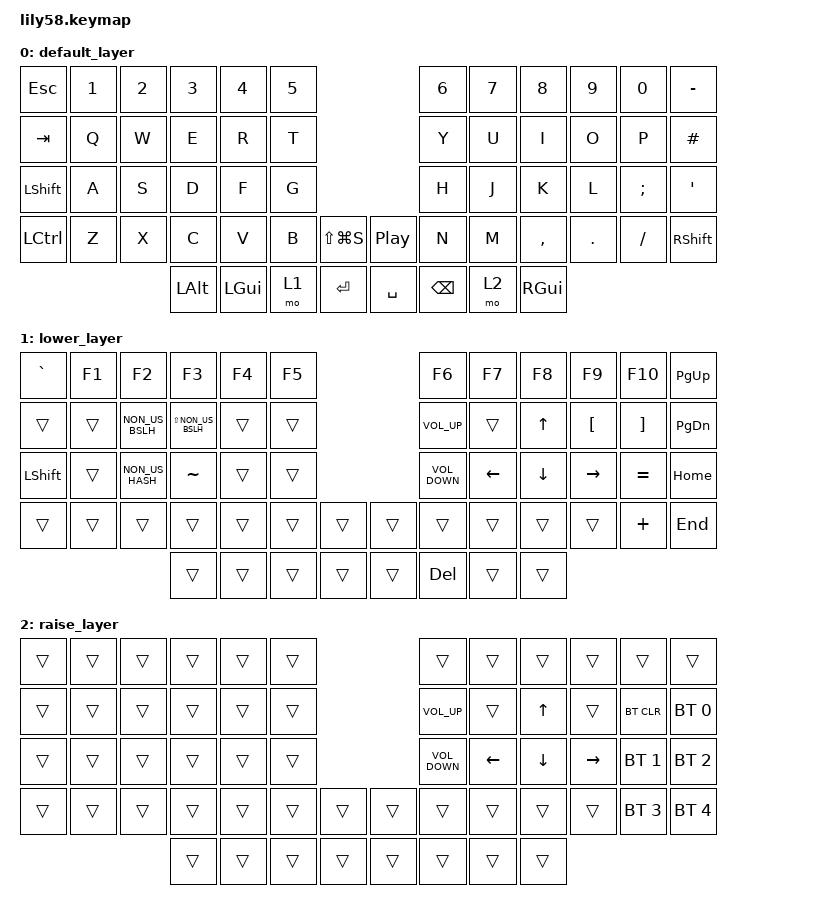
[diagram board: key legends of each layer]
/*
 * Copyright (c) 2020 The ZMK Contributors
 *
 * SPDX-License-Identifier: MIT
 */

#include <behaviors.dtsi>
#include <dt-bindings/zmk/bt.h>
#include <dt-bindings/zmk/keys.h>

/ {
    keymap {
        compatible = "zmk,keymap";

        default_layer {
            bindings = <
&kp ESC   &kp N1  &kp N2  &kp N3    &kp N4    &kp N5                            &kp N6    &kp N7  &kp N8     &kp N9   &kp N0    &kp MINUS
&kp TAB   &kp Q   &kp W   &kp E     &kp R     &kp T                             &kp Y     &kp U   &kp I      &kp O    &kp P     &kp POUND
&kp LSHIFT&kp A   &kp S   &kp D     &kp F     &kp G                             &kp H     &kp J   &kp K      &kp L    &kp SEMI  &kp SQT
&kp LCTRL &kp Z   &kp X   &kp C     &kp V     &kp B   &kp LS(LG(S))  &kp C_PP   &kp N     &kp M   &kp COMMA  &kp DOT  &kp FSLH  &kp RSHFT
                          &kp LALT  &kp LGUI  &mo 1   &kp RETURN     &kp SPACE  &kp BSPC  &mo 2   &kp RGUI
            >;
        };

        lower_layer {
            bindings = <
&kp GRAVE     &kp F1  &kp F2           &kp F3               &kp F4  &kp F5                  &kp F6             &kp F7    &kp F8    &kp F9     &kp F10    &kp PG_UP
&trans        &trans  &kp NON_US_BSLH  &kp LS(NON_US_BSLH)  &trans  &trans                  &kp C_VOLUME_UP    &trans    &kp UP    &kp LBKT   &kp RBKT   &kp PG_DN
&kp LEFT_SHIFT&trans  &kp NON_US_HASH  &kp TILDE            &trans  &trans                  &kp C_VOLUME_DOWN  &kp LEFT  &kp DOWN  &kp RIGHT  &kp EQUAL  &kp HOME
&trans        &trans  &trans           &trans               &trans  &trans  &trans  &trans  &trans             &trans    &trans    &trans     &kp PLUS   &kp END
                                       &trans               &trans  &trans  &trans  &trans  &kp DEL            &trans    &trans
            >;
        };

        raise_layer {
            bindings = <
&trans&trans  &trans  &trans  &trans  &trans                  &trans             &trans    &trans    &trans     &trans        &trans
&trans&trans  &trans  &trans  &trans  &trans                  &kp C_VOLUME_UP    &trans    &kp UP    &trans     &bt BT_CLR    &bt BT_SEL 0
&trans&trans  &trans  &trans  &trans  &trans                  &kp C_VOLUME_DOWN  &kp LEFT  &kp DOWN  &kp RIGHT  &bt BT_SEL 1  &bt BT_SEL 2
&trans&trans  &trans  &trans  &trans  &trans  &trans  &trans  &trans             &trans    &trans    &trans     &bt BT_SEL 3  &bt BT_SEL 4
                      &trans  &trans  &trans  &trans  &trans  &trans             &trans    &trans
            >;
        };
    };
};
